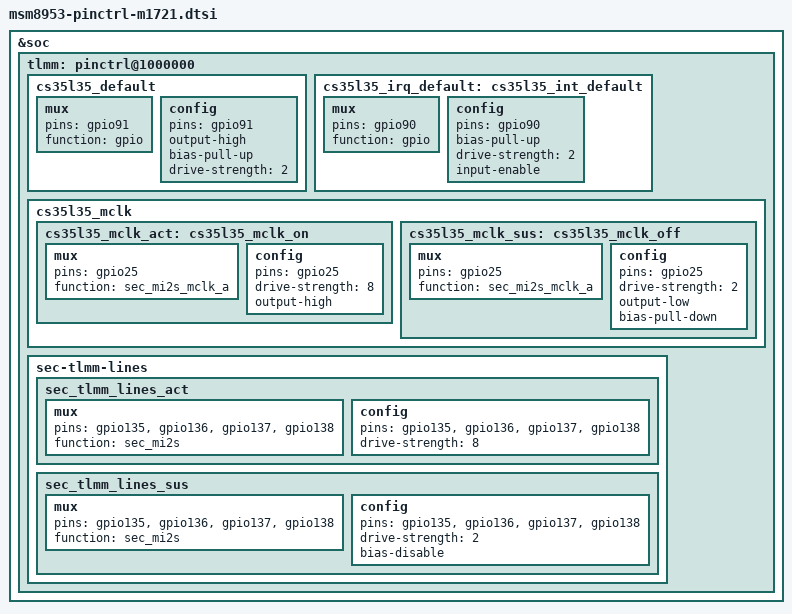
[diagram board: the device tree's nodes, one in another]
/*
 * Copyright (c) 2017, The Linux Foundation. All rights reserved.
 *
 * This program is free software; you can redistribute it and/or modify
 * it under the terms of the GNU General Public License version 2 and
 * only version 2 as published by the Free Software Foundation.
 *
 * This program is distributed in the hope that it will be useful,
 * but WITHOUT ANY WARRANTY; without even the implied warranty of
 * MERCHANTABILITY or FITNESS FOR A PARTICULAR PURPOSE.  See the
 * GNU General Public License for more details.
 */

&soc {
	tlmm: pinctrl@1000000 {
		cs35l35_default {
			mux {
				pins = "gpio91";
				function = "gpio";
			};

			config {
				pins = "gpio91";
				output-high;
				bias-pull-up;
				drive-strength = <2>;
			};
		};

		cs35l35_irq_default: cs35l35_int_default {
			mux {
				pins = "gpio90";
				function = "gpio";
			};

			config {
				pins = "gpio90";
				bias-pull-up;
				drive-strength = <2>;
				input-enable;
			};
		};
		
		cs35l35_mclk {
			cs35l35_mclk_act: cs35l35_mclk_on {
				mux {
					pins = "gpio25";
					function = "sec_mi2s_mclk_a";
				};

				config {
					pins = "gpio25";
					drive-strength = <8>;
					output-high;
				};
			};

			cs35l35_mclk_sus: cs35l35_mclk_off {
				mux {
					pins = "gpio25";
					function = "sec_mi2s_mclk_a";
				};

				config {
					pins = "gpio25";
					drive-strength = <2>;
					output-low;
					bias-pull-down;
				};
			};
		};
		
		sec-tlmm-lines {
			sec_tlmm_lines_act: sec_tlmm_lines_act {
				mux {
					pins = "gpio135", "gpio136", "gpio137", "gpio138";
					function = "sec_mi2s";
				};

				config {
					pins = "gpio135", "gpio136", "gpio137", "gpio138";
					drive-strength = <8>;
				};
			};

			sec_tlmm_lines_sus: sec_tlmm_lines_sus {
				mux {
					pins = "gpio135", "gpio136", "gpio137", "gpio138";
					function = "sec_mi2s";
				};

				config {
					pins = "gpio135", "gpio136", "gpio137", "gpio138";
					drive-strength = <2>;
					bias-disable;
				};
			};
		};
	};
};

